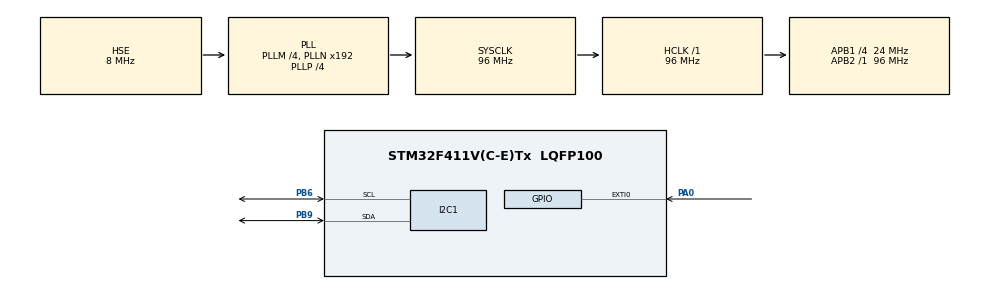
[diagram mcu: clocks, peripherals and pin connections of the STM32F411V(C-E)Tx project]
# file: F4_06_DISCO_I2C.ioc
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I2C1.I2C_Mode=I2C_Fast
Mcu.Family=STM32F4
Mcu.Name=STM32F411V(C-E)Tx
Mcu.Package=LQFP100
NVIC.PriorityGroup=NVIC_PRIORITYGROUP_0
PA0-WKUP.GPIO_ModeDefaultEXTI=GPIO_MODE_EVT_RISING
PA0-WKUP.Signal=GPXTI0
PA13.GPIO_Label=SWDIO
PA13.Mode=Serial_Wire
PA13.Signal=SYS_JTMS-SWDIO
PA14.GPIO_Label=SWCLK
PA14.Mode=Serial_Wire
PA14.Signal=SYS_JTCK-SWCLK
PB3.GPIO_Label=SWO
PB3.Signal=SYS_JTDO-SWO
PB6.Mode=I2C
PB6.Signal=I2C1_SCL
PB9.Mode=I2C
PB9.Signal=I2C1_SDA
PH0\ -\ OSC_IN.GPIO_Label=PH0-OSC_IN
PH0\ -\ OSC_IN.Mode=HSE-External-Oscillator
PH0\ -\ OSC_IN.Signal=RCC_OSC_IN
PH1\ -\ OSC_OUT.GPIO_Label=PH1-OSC_OUT
PH1\ -\ OSC_OUT.Mode=HSE-External-Oscillator
PH1\ -\ OSC_OUT.Signal=RCC_OSC_OUT
ProjectManager.HeapSize=0x200
ProjectManager.StackSize=0x400
ProjectManager.TargetToolchain=STM32CubeIDE
RCC.48MHZClocksFreq_Value=48000000
RCC.AHBFreq_Value=96000000
RCC.APB1CLKDivider=RCC_HCLK_DIV4
RCC.APB1Freq_Value=24000000
RCC.APB1TimFreq_Value=48000000
RCC.APB2Freq_Value=96000000
RCC.APB2TimFreq_Value=96000000
RCC.CortexFreq_Value=96000000
RCC.HCLKFreq_Value=96000000
RCC.HSE_VALUE=8000000
RCC.HSI_VALUE=16000000
RCC.PLLI2SM=5
RCC.PLLI2SN=200
RCC.PLLM=4
RCC.PLLP=RCC_PLLP_DIV4
RCC.PLLQ=8
RCC.PLLSourceVirtual=RCC_PLLSOURCE_HSE
RCC.SYSCLKFreq_VALUE=96000000
RCC.SYSCLKSource=RCC_SYSCLKSOURCE_PLLCLK
RCC.VCOOutputFreq_Value=384000000
board=STM32F411E-DISCO

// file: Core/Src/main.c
/* USER CODE BEGIN Header */
/**
  ******************************************************************************
  * @file           : main.c
  * @brief          : Main program body
  ******************************************************************************
  * @attention
  *
  * Copyright (c) 2023 STMicroelectronics.
  * All rights reserved.
  *
  * This software is licensed under terms that can be found in the LICENSE file
  * in the root directory of this software component.
  * If no LICENSE file comes with this software, it is provided AS-IS.
  *
  ******************************************************************************
  */
/* USER CODE END Header */
#include "main.h"
#include "i2c.h"
#include "gpio.h"

/* USER CODE BEGIN Includes */
#include <limits.h>
/* USER CODE END Includes */

/* USER CODE BEGIN PD */
#define LSM303_ACC_ADRESS (0x19 << 1)	// adres akcelerometru: 0011 001x
#define LSM303_ACC_CTRL_REG1_A 0x20		// rejestr ustawien 1
#define LSM303_ACC_OUT_Z_H_A 0x2D		// 0010 1101
#define LSM303_ACC_OUT_Z_L_A 0x2C		// 0010 1100

// mlodzy bajt danych osi Z z najstarszym bitem ustawionym na 1 w celu
// wymuszenia autoinkrementacji adresow rejestru w urzadzeniu docelowym
#define LSM303_ACC_Z_L_A_MULTI_READ (LSM303_ACC_OUT_Z_L_A | 0x80)

// CTRL_REG1_A = [ODR3][ODR2][ODR1][ODR0][LPEN][ZEN][YEN][XEN]
#define LSM303_ACC_Z_ENABLE 0x04		// 0000 0100
#define LSM303_ACC_100HZ 0x50			// 0101 0000

#define LSM303_ACC_RESOLUTION 2.0		// Maksymalna wartosc przyspieszenia [g]

/* USER CODE END PD */

/* USER CODE BEGIN PV */
uint8_t Settings = LSM303_ACC_Z_ENABLE | LSM303_ACC_100HZ;
uint8_t Data[2];						// Zmienna do bezposredniego odczytu z akcelerometru
int16_t Zaxis = 0;						// Zawiera przeksztalcona forme odczytanych danych
float Zaxis_g = 0;						// Zawiera przyspieszenie w osi przeksztalcone na jednostke fizyczna [g]
/* USER CODE END PV */

void SystemClock_Config(void);

int main(void)
{

  /* MCU Configuration--------------------------------------------------------*/

  /* Reset of all peripherals, Initializes the Flash interface and the Systick. */
  HAL_Init();

  /* Configure the system clock */
  SystemClock_Config();

  /* Initialize all configured peripherals */
  MX_GPIO_Init();
  MX_I2C1_Init();
  /* USER CODE BEGIN 2 */
  HAL_I2C_Mem_Write(&hi2c1, LSM303_ACC_ADRESS, LSM303_ACC_CTRL_REG1_A, 1, &Settings, 1, 100);
  /* USER CODE END 2 */

  /* Infinite loop */
  /* USER CODE BEGIN WHILE */
  while (1)
  {
	  HAL_I2C_Mem_Read(&hi2c1, LSM303_ACC_ADRESS, LSM303_ACC_Z_L_A_MULTI_READ, 1, Data, 2, 100);
	  Zaxis = (Data[1] << 8 | Data[0]);
	  Zaxis_g = ((float) Zaxis * LSM303_ACC_RESOLUTION) / (float) INT16_MAX;
    /* USER CODE END WHILE */

  }
}

void SystemClock_Config(void)
{
  RCC_OscInitTypeDef RCC_OscInitStruct = {0};
  RCC_ClkInitTypeDef RCC_ClkInitStruct = {0};

  /** Configure the main internal regulator output voltage
  */
  __HAL_RCC_PWR_CLK_ENABLE();
  __HAL_PWR_VOLTAGESCALING_CONFIG(PWR_REGULATOR_VOLTAGE_SCALE1);

  /** Initializes the RCC Oscillators according to the specified parameters
  * in the RCC_OscInitTypeDef structure.
  */
  RCC_OscInitStruct.OscillatorType = RCC_OSCILLATORTYPE_HSE;
  RCC_OscInitStruct.HSEState = RCC_HSE_ON;
  RCC_OscInitStruct.PLL.PLLState = RCC_PLL_ON;
  RCC_OscInitStruct.PLL.PLLSource = RCC_PLLSOURCE_HSE;
  RCC_OscInitStruct.PLL.PLLM = 4;
  RCC_OscInitStruct.PLL.PLLN = 192;
  RCC_OscInitStruct.PLL.PLLP = RCC_PLLP_DIV4;
  RCC_OscInitStruct.PLL.PLLQ = 8;
  if (HAL_RCC_OscConfig(&RCC_OscInitStruct) != HAL_OK)
  {
    Error_Handler();
  }

  /** Initializes the CPU, AHB and APB buses clocks
  */
  RCC_ClkInitStruct.ClockType = RCC_CLOCKTYPE_HCLK|RCC_CLOCKTYPE_SYSCLK
                              |RCC_CLOCKTYPE_PCLK1|RCC_CLOCKTYPE_PCLK2;
  RCC_ClkInitStruct.SYSCLKSource = RCC_SYSCLKSOURCE_PLLCLK;
  RCC_ClkInitStruct.AHBCLKDivider = RCC_SYSCLK_DIV1;
  RCC_ClkInitStruct.APB1CLKDivider = RCC_HCLK_DIV4;
  RCC_ClkInitStruct.APB2CLKDivider = RCC_HCLK_DIV1;

  if (HAL_RCC_ClockConfig(&RCC_ClkInitStruct, FLASH_LATENCY_3) != HAL_OK)
  {
    Error_Handler();
  }
}

void Error_Handler(void)
{
  __disable_irq();
  while (1)
  {
  }
}
